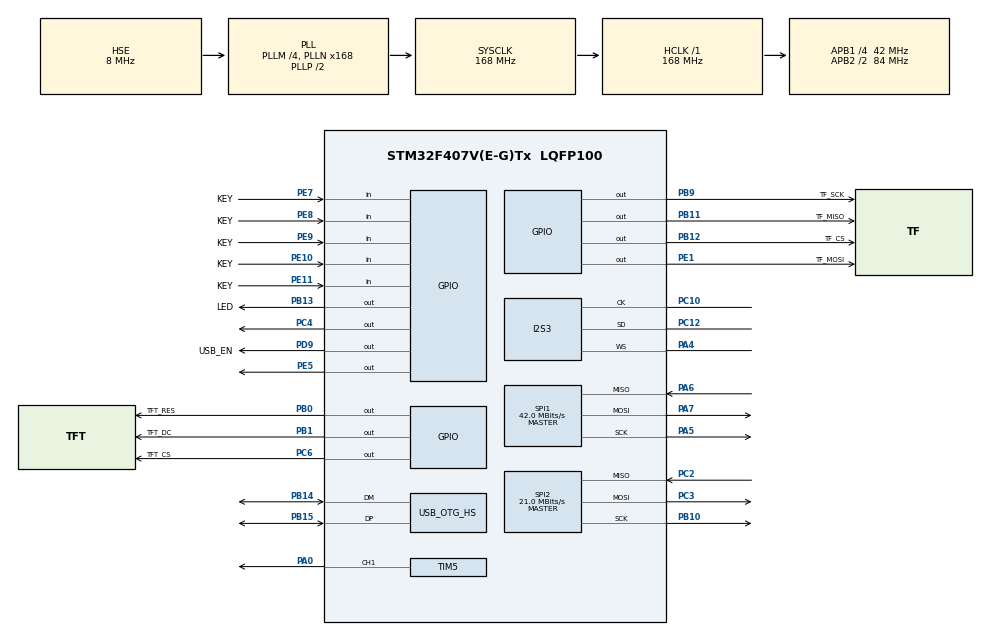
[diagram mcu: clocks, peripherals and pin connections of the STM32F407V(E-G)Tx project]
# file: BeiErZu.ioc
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FATFS._USE_FIND=1
FATFS._USE_LFN=3
FATFS._USE_MUTEX=0
FREERTOS.Tasks01=defaultTask,24,128,StartDefaultTask,Default,NULL,Dynamic,NULL,NULL
I2S3.AudioFreq=I2S_AUDIOFREQ_44K
I2S3.ErrorAudioFreq=0.26 %
I2S3.FullDuplexMode=I2S_FULLDUPLEXMODE_DISABLE
I2S3.Instance=SPI$Index
I2S3.RealAudioFreq=44.117 KHz
I2S3.VirtualMode=I2S_MODE_MASTER
Mcu.Family=STM32F4
Mcu.Name=STM32F407V(E-G)Tx
Mcu.Package=LQFP100
NVIC.OTG_HS_IRQn=true\:5\:0\:false\:false\:true\:true\:false\:true\:true
NVIC.PriorityGroup=NVIC_PRIORITYGROUP_4
NVIC.TIM1_TRG_COM_TIM11_IRQn=true\:15\:0\:false\:false\:true\:false\:false\:true\:true
NVIC.TimeBase=TIM1_TRG_COM_TIM11_IRQn
NVIC.TimeBaseIP=TIM11
PA0-WKUP.Signal=S_TIM5_CH1
PA13.Mode=Serial_Wire
PA13.Signal=SYS_JTMS-SWDIO
PA14.Mode=Serial_Wire
PA14.Signal=SYS_JTCK-SWCLK
PA4.Mode=Half_Duplex_Master
PA4.Signal=I2S3_WS
PA5.Mode=Full_Duplex_Master
PA5.Signal=SPI1_SCK
PA6.Mode=Full_Duplex_Master
PA6.Signal=SPI1_MISO
PA7.Mode=Full_Duplex_Master
PA7.Signal=SPI1_MOSI
PB0.GPIO_Label=TFT_RES
PB0.Signal=GPIO_Output
PB1.GPIO_Label=TFT_DC
PB1.Signal=GPIO_Output
PB10.Mode=Full_Duplex_Master
PB10.Signal=SPI2_SCK
PB11.GPIO_Label=TF_MISO
PB11.Signal=GPIO_Output
PB12.GPIO_Label=TF_CS
PB12.Signal=GPIO_Output
PB13.GPIO_Label=LED
PB13.GPIO_ModeDefaultOutputPP=GPIO_MODE_OUTPUT_PP
PB13.GPIO_PuPd=GPIO_NOPULL
PB13.PinState=GPIO_PIN_RESET
PB13.Signal=GPIO_Output
PB14.Mode=Host_FS
PB14.Signal=USB_OTG_HS_DM
PB15.Mode=Host_FS
PB15.Signal=USB_OTG_HS_DP
PB9.GPIO_Label=TF_SCK
PB9.Signal=GPIO_Output
PC10.Mode=Half_Duplex_Master
PC10.Signal=I2S3_CK
PC12.Mode=Half_Duplex_Master
PC12.Signal=I2S3_SD
PC14-OSC32_IN.Mode=LSE-External-Oscillator
PC14-OSC32_IN.Signal=RCC_OSC32_IN
PC15-OSC32_OUT.Mode=LSE-External-Oscillator
PC15-OSC32_OUT.Signal=RCC_OSC32_OUT
PC2.Mode=Full_Duplex_Master
PC2.Signal=SPI2_MISO
PC3.Mode=Full_Duplex_Master
PC3.Signal=SPI2_MOSI
PC4.Signal=GPIO_Output
PC6.GPIO_Label=TFT_CS
PC6.Signal=GPIO_Output
PD9.GPIO_Label=USB_EN
PD9.GPIO_ModeDefaultOutputPP=GPIO_MODE_OUTPUT_PP
PD9.PinState=GPIO_PIN_SET
PD9.Signal=GPIO_Output
PE1.GPIO_Label=TF_MOSI
PE1.Signal=GPIO_Output
PE10.GPIO_Label=KEY
PE10.GPIO_Mode=GPIO_MODE_INPUT
PE10.GPIO_PuPd=GPIO_PULLUP
PE10.Signal=GPIO_Input
PE11.GPIO_Label=KEY
PE11.GPIO_Mode=GPIO_MODE_INPUT
PE11.GPIO_PuPd=GPIO_PULLUP
PE11.Signal=GPIO_Input
PE5.Signal=GPIO_Output
PE7.GPIO_Label=KEY
PE7.GPIO_Mode=GPIO_MODE_INPUT
PE7.GPIO_PuPd=GPIO_PULLUP
PE7.Signal=GPIO_Input
PE8.GPIO_Label=KEY
PE8.GPIO_Mode=GPIO_MODE_INPUT
PE8.GPIO_PuPd=GPIO_PULLUP
PE8.Signal=GPIO_Input
PE9.GPIO_Label=KEY
PE9.GPIO_Mode=GPIO_MODE_INPUT
PE9.GPIO_PuPd=GPIO_PULLUP
PE9.Signal=GPIO_Input
PH0-OSC_IN.Mode=HSE-External-Oscillator
PH0-OSC_IN.Signal=RCC_OSC_IN
PH1-OSC_OUT.Mode=HSE-External-Oscillator
PH1-OSC_OUT.Signal=RCC_OSC_OUT
ProjectManager.HeapSize=0x200
ProjectManager.StackSize=0x400
ProjectManager.TargetToolchain=CMake
RCC.48MHZClocksFreq_Value=48000000
RCC.AHBFreq_Value=168000000
RCC.APB1CLKDivider=RCC_HCLK_DIV4
RCC.APB1Freq_Value=42000000
RCC.APB1TimFreq_Value=84000000
RCC.APB2CLKDivider=RCC_HCLK_DIV2
RCC.APB2Freq_Value=84000000
RCC.APB2TimCLKDivider=2
RCC.APB2TimFreq_Value=168000000
RCC.CortexFreq_Value=168000000
RCC.HCLKFreq_Value=168000000
RCC.HSE_VALUE=8000000
RCC.HSI_VALUE=16000000
RCC.PLLM=4
RCC.PLLN=168
RCC.PLLQ=7
RCC.SYSCLKFreq_VALUE=168000000
RCC.SYSCLKSource=RCC_SYSCLKSOURCE_PLLCLK
RCC.VCOOutputFreq_Value=336000000
SH.S_TIM5_CH1.0=TIM5_CH1,PWM Generation1 CH1
SPI1.BaudRatePrescaler=SPI_BAUDRATEPRESCALER_2
SPI1.CLKPhase=SPI_PHASE_1EDGE
SPI1.CLKPolarity=SPI_POLARITY_LOW
SPI1.CalculateBaudRate=42.0 MBits/s
SPI1.Direction=SPI_DIRECTION_2LINES
SPI1.Mode=SPI_MODE_MASTER
SPI1.VirtualType=VM_MASTER
SPI2.CalculateBaudRate=21.0 MBits/s
SPI2.Direction=SPI_DIRECTION_2LINES
SPI2.Mode=SPI_MODE_MASTER
SPI2.VirtualType=VM_MASTER
TIM5.Channel-PWM\ Generation1\ CH1=TIM_CHANNEL_1
TIM5.Period=4199
USB_HOST.USBH_PROCESS_STACK_SIZE=1024
USB_HOST.SW_VBUS_DRIVE_HID_HS=true
USB_HOST.USBH_HandleTypeDef-HID_HS=hUsbHostHS
USB_HOST.VirtualModeHS=Hid
USB_OTG_HS.VirtualMode-Host_FS=Host_FS
VP_FATFS_VS_Generic.Mode=User_defined
VP_FREERTOS_VS_CMSIS_V2.Mode=CMSIS_V2
VP_SYS_VS_tim11.Mode=TIM11
VP_TIM5_VS_ClockSourceINT.Mode=Internal
VP_USB_HOST_VS_USB_HOST_HID_HS.Mode=HID_HS
board=custom

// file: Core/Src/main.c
/* USER CODE BEGIN Header */
/**
  ******************************************************************************
  * @file           : main.c
  * @brief          : Main program body
  ******************************************************************************
  * @attention
  *
  * Copyright (c) 2026 STMicroelectronics.
  * All rights reserved.
  *
  * This software is licensed under terms that can be found in the LICENSE file
  * in the root directory of this software component.
  * If no LICENSE file comes with this software, it is provided AS-IS.
  *
  ******************************************************************************
  */
/* USER CODE END Header */
#include "main.h"
#include "cmsis_os.h"
#include "fatfs.h"
#include "i2s.h"
#include "spi.h"
#include "tim.h"
#include "usb_host.h"
#include "gpio.h"

/* USER CODE BEGIN Includes */
#include "app_backlight.h"
#include "app_led.h"
#include "app_lcd.h"
#include "app_lvgl.h"
/* USER CODE END Includes */

void SystemClock_Config(void);
void MX_FREERTOS_Init(void);

/* USER CODE BEGIN 0 */
uint8_t lcd_num = 0;
/* USER CODE END 0 */

int main(void)
{

  /* MCU Configuration--------------------------------------------------------*/

  /* Reset of all peripherals, Initializes the Flash interface and the Systick. */
  HAL_Init();

  /* Configure the system clock */
  SystemClock_Config();

  /* Initialize all configured peripherals */
  MX_GPIO_Init();
  MX_SPI1_Init();
  MX_SPI2_Init();
  MX_TIM5_Init();
  MX_I2S3_Init();
  MX_FATFS_Init();
  /* USER CODE BEGIN 2 */
  app_backlight_init(50);

  /* USER CODE END 2 */

  /* Init scheduler */
  osKernelInitialize();

  /* Call init function for freertos objects (in cmsis_os2.c) */
  MX_FREERTOS_Init();

  /* Start scheduler */
  osKernelStart();

  /* We should never get here as control is now taken by the scheduler */

  /* Infinite loop */
  while (1)
  {

  }
}

void SystemClock_Config(void)
{
  RCC_OscInitTypeDef RCC_OscInitStruct = {0};
  RCC_ClkInitTypeDef RCC_ClkInitStruct = {0};

  /** Configure the main internal regulator output voltage
  */
  __HAL_RCC_PWR_CLK_ENABLE();
  __HAL_PWR_VOLTAGESCALING_CONFIG(PWR_REGULATOR_VOLTAGE_SCALE1);

  /** Initializes the RCC Oscillators according to the specified parameters
  * in the RCC_OscInitTypeDef structure.
  */
  RCC_OscInitStruct.OscillatorType = RCC_OSCILLATORTYPE_HSE;
  RCC_OscInitStruct.HSEState = RCC_HSE_ON;
  RCC_OscInitStruct.PLL.PLLState = RCC_PLL_ON;
  RCC_OscInitStruct.PLL.PLLSource = RCC_PLLSOURCE_HSE;
  RCC_OscInitStruct.PLL.PLLM = 4;
  RCC_OscInitStruct.PLL.PLLN = 168;
  RCC_OscInitStruct.PLL.PLLP = RCC_PLLP_DIV2;
  RCC_OscInitStruct.PLL.PLLQ = 7;
  if (HAL_RCC_OscConfig(&RCC_OscInitStruct) != HAL_OK)
  {
    Error_Handler();
  }

  /** Initializes the CPU, AHB and APB buses clocks
  */
  RCC_ClkInitStruct.ClockType = RCC_CLOCKTYPE_HCLK|RCC_CLOCKTYPE_SYSCLK
                              |RCC_CLOCKTYPE_PCLK1|RCC_CLOCKTYPE_PCLK2;
  RCC_ClkInitStruct.SYSCLKSource = RCC_SYSCLKSOURCE_PLLCLK;
  RCC_ClkInitStruct.AHBCLKDivider = RCC_SYSCLK_DIV1;
  RCC_ClkInitStruct.APB1CLKDivider = RCC_HCLK_DIV4;
  RCC_ClkInitStruct.APB2CLKDivider = RCC_HCLK_DIV2;

  if (HAL_RCC_ClockConfig(&RCC_ClkInitStruct, FLASH_LATENCY_5) != HAL_OK)
  {
    Error_Handler();
  }
}

void HAL_TIM_PeriodElapsedCallback(TIM_HandleTypeDef *htim)
{
  if (htim->Instance == TIM11) {
    HAL_IncTick();
    lv_tick_inc(1);
  }
}

void Error_Handler(void)
{
  __disable_irq();
  while (1)
  {
  }
}
